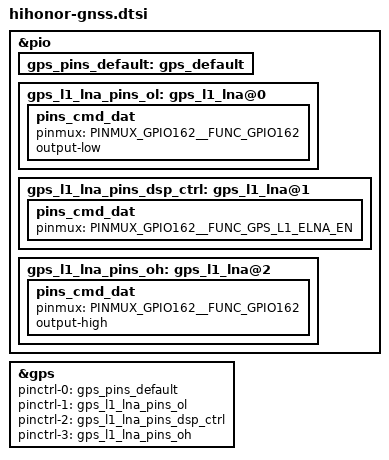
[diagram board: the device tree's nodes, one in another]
/* GPS GPIO standardization start */
&pio {
	gps_pins_default: gps_default {
	};

	gps_l1_lna_pins_ol: gps_l1_lna@0 {
		pins_cmd_dat {
			pinmux = <PINMUX_GPIO162__FUNC_GPIO162>;
			output-low;
		};
	};
	gps_l1_lna_pins_dsp_ctrl: gps_l1_lna@1 {
		pins_cmd_dat {
			pinmux = <PINMUX_GPIO162__FUNC_GPS_L1_ELNA_EN>;
		};
	};
	gps_l1_lna_pins_oh: gps_l1_lna@2 {
		pins_cmd_dat {
			pinmux = <PINMUX_GPIO162__FUNC_GPIO162>;
			output-high;
		};
	};
};

&gps {
	pinctrl-names = "default",
		"gps_l1_lna_disable",
		"gps_l1_lna_dsp_ctrl",
		"gps_l1_lna_enable";
	pinctrl-0 = <&gps_pins_default>;
	pinctrl-1 = <&gps_l1_lna_pins_ol>;
	pinctrl-2 = <&gps_l1_lna_pins_dsp_ctrl>;
	pinctrl-3 = <&gps_l1_lna_pins_oh>;
	status = "okay";
};
/* GPS GPIO standardization end */
